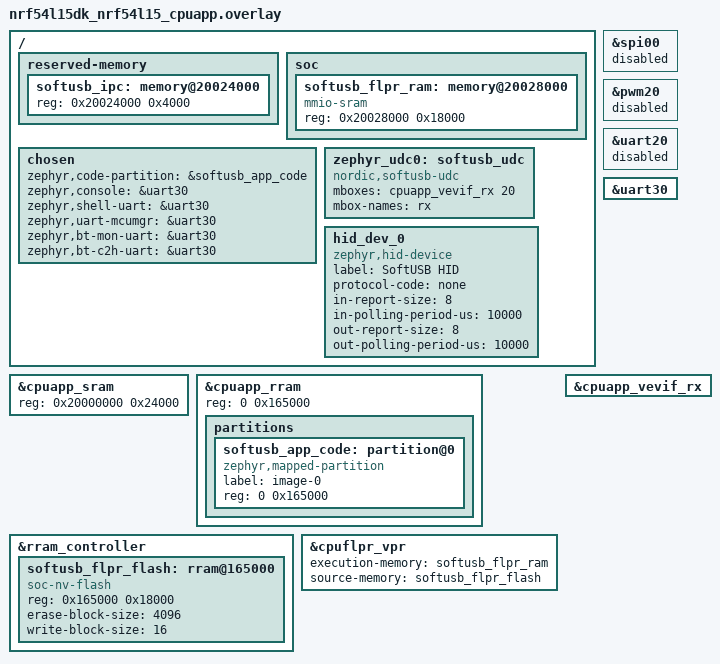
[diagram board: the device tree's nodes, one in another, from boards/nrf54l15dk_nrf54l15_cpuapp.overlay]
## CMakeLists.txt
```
cmake_minimum_required(VERSION 3.20.0)
list(APPEND DTS_ROOT ${CMAKE_CURRENT_SOURCE_DIR})
find_package(Zephyr REQUIRED HINTS $ENV{ZEPHYR_BASE})
project(softusb_device)
target_include_directories(app PRIVATE include ${ZEPHYR_BASE}/drivers/usb/udc)
target_sources(app PRIVATE src/main.c src/udc_softusb.c)
```

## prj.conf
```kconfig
CONFIG_MAIN_STACK_SIZE=4096
CONFIG_HEAP_MEM_POOL_SIZE=4096
CONFIG_GPIO=y
CONFIG_SPI=n
CONFIG_FLASH=n
CONFIG_PM=n
CONFIG_NORDIC_VPR_LAUNCHER=y
CONFIG_DCACHE=n
CONFIG_MBOX=y

CONFIG_USB_DEVICE_STACK_NEXT=y
CONFIG_USBD_HID_SUPPORT=y
CONFIG_UDC_BUF_COUNT=32

CONFIG_LOG=y
CONFIG_LOG_MODE_DEFERRED=y
CONFIG_USBD_LOG_LEVEL_WRN=y
CONFIG_USBD_HID_LOG_LEVEL_WRN=y
CONFIG_UDC_DRIVER_LOG_LEVEL_INF=y
```

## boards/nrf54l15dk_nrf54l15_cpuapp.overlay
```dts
/* App 144 KiB, IPC 16 KiB, FLPR 96 KiB. No overlap. */
/ {
    reserved-memory {
        #address-cells = <1>;
        #size-cells = <1>;
        ranges;
        softusb_ipc: memory@20024000 { reg = <0x20024000 0x4000>; };
    };
    soc {
        softusb_flpr_ram: memory@20028000 {
            compatible = "mmio-sram";
            reg = <0x20028000 0x18000>;
        };
    };
};
&cpuapp_sram { reg = <0x20000000 0x24000>; ranges = <0 0x20000000 0x24000>; };
&cpuapp_rram {
    reg = <0 0x165000>;
    ranges = <0 0 0x165000>;
    /delete-node/ partitions;
    partitions {
        #address-cells = <1>;
        #size-cells = <1>;
        softusb_app_code: partition@0 {
            compatible = "zephyr,mapped-partition";
            label = "image-0";
            reg = <0 0x165000>;
        };
    };
};
/ { chosen { zephyr,code-partition = &softusb_app_code; }; };
&rram_controller {
    softusb_flpr_flash: rram@165000 {
        compatible = "soc-nv-flash";
        reg = <0x165000 0x18000>;
        erase-block-size = <4096>;
        write-block-size = <16>;
    };
};
&cpuflpr_vpr {
    status = "okay";
    execution-memory = <&softusb_flpr_ram>;
    source-memory = <&softusb_flpr_flash>;
};
/* Never let flash/pinctrl claim the provisional bench pins. */
&spi00 { status = "disabled"; };
&pwm20 { status = "disabled"; };
/* Reserve P1.04..07 + P1.11/12 for future app-core PD control. */
&uart20 { status = "disabled"; };
&uart30 { status = "okay"; };
/ {
    chosen {
        zephyr,console = &uart30;
        zephyr,shell-uart = &uart30;
        zephyr,uart-mcumgr = &uart30;
        zephyr,bt-mon-uart = &uart30;
        zephyr,bt-c2h-uart = &uart30;
    };
};

&cpuapp_vevif_rx { status = "okay"; };

/ {
    zephyr_udc0: softusb_udc {
        compatible = "nordic,softusb-udc";
        mboxes = <&cpuapp_vevif_rx 20>;
        mbox-names = "rx";
        status = "okay";
    };

    /* Vendor-defined HID: harmless to the host (no keys, no pointer). LS
     * limits: 8-byte reports, interrupt endpoints polled every 10 ms.
     */
    hid_dev_0: hid_dev_0 {
        compatible = "zephyr,hid-device";
        label = "SoftUSB HID";
        protocol-code = "none";
        in-report-size = <8>;
        in-polling-period-us = <10000>;
        out-report-size = <8>;
        out-polling-period-us = <10000>;
    };
};
```

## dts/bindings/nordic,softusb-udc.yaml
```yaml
description: |
  SoftUSB low-speed USB device controller. The bus is bit-banged on P2.00 (D+)
  and P2.01 (D-) by an HPF personality on the FLPR core; the app core runs the
  Zephyr UDC driver. mboxes must name the FLPR->app VEVIF event as "rx".

compatible: "nordic,softusb-udc"

include: base.yaml
```

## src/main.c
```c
/*
 * SoftUSB demo: a low-speed vendor-defined HID device on the stock Zephyr
 * USB device stack (device_next), running over the FLPR bit-banged PHY.
 *
 * The vendor usage page means the host binds hidraw only: no keystrokes or
 * pointer motion. Each 8-byte OUT report is echoed back as the next IN
 * report; otherwise an IN report with a counter is sent every 500 ms.
 */
#include <string.h>
#include <zephyr/kernel.h>
#include <zephyr/sys/byteorder.h>
#include <zephyr/device.h>
#include <zephyr/usb/usbd.h>
#include <zephyr/usb/class/usbd_hid.h>
#include <zephyr/logging/log.h>
#include <zephyr/drivers/clock_control/nrf_clock_control.h>
#include "softusb_ipc.h"

LOG_MODULE_REGISTER(main, LOG_LEVEL_INF);

USBD_DEVICE_DEFINE(su_usbd, DEVICE_DT_GET(DT_NODELABEL(zephyr_udc0)), 0x2fe3, 0x0100);
USBD_DESC_LANG_DEFINE(su_lang);
USBD_DESC_MANUFACTURER_DEFINE(su_mfr, "HPF SoftUSB");
USBD_DESC_PRODUCT_DEFINE(su_product, "nRF54L15 FLPR LS HID");
USBD_DESC_CONFIG_DEFINE(su_cfg_desc, "LS configuration");
USBD_CONFIGURATION_DEFINE(su_config, 0, 50, &su_cfg_desc);

static const uint8_t report_desc[] = {
	0x06, 0x00, 0xFF, /* Usage Page (Vendor 0xFF00) */
	0x09, 0x01,       /* Usage (1) */
	0xA1, 0x01,       /* Collection (Application) */
	0x15, 0x00,       /*   Logical Minimum (0) */
	0x26, 0xFF, 0x00, /*   Logical Maximum (255) */
	0x75, 0x08,       /*   Report Size (8) */
	0x95, 0x08,       /*   Report Count (8) */
	0x09, 0x01,       /*   Usage (1) */
	0x81, 0x02,       /*   Input (Data, Var, Abs) */
	0x09, 0x01,       /*   Usage (1) */
	0x91, 0x02,       /*   Output (Data, Var, Abs) */
	0xC0,             /* End Collection */
};

UDC_STATIC_BUF_DEFINE(in_report, 8);
static uint8_t echo[8];
static volatile bool echo_pending;
static volatile bool hid_ready;
static K_SEM_DEFINE(report_done, 1, 1);
static K_SEM_DEFINE(echo_sem, 0, 1);

static void iface_ready(const struct device *dev, const bool ready)
{
	LOG_INF("HID interface %s", ready ? "ready" : "not ready");
	hid_ready = ready;
}

static int get_report(const struct device *dev, const uint8_t type, const uint8_t id,
		      const uint16_t len, uint8_t *const buf)
{
	return 0;
}

static int set_report(const struct device *dev, const uint8_t type, const uint8_t id,
		      const uint16_t len, const uint8_t *const buf)
{
	return 0;
}

static void output_report(const struct device *dev, const uint16_t len,
			  const uint8_t *const buf)
{
	memcpy(echo, buf, MIN(len, sizeof(echo)));
	echo_pending = true;
	k_sem_give(&echo_sem);
	LOG_INF("OUT report %02x %02x %02x %02x %02x %02x %02x %02x", echo[0], echo[1],
		echo[2], echo[3], echo[4], echo[5], echo[6], echo[7]);
}

static void input_report_done(const struct device *dev, const uint8_t *const report)
{
	k_sem_give(&report_done);
}

static const struct hid_device_ops hid_ops = {
	.iface_ready = iface_ready,
	.get_report = get_report,
	.set_report = set_report,
	.output_report = output_report,
	.input_report_done = input_report_done,
};

static void msg_cb(struct usbd_context *const ctx, const struct usbd_msg *const msg)
{
	LOG_INF("USBD message: %s", usbd_msg_type_string(msg->type));
}

static int usb_setup(void)
{
	int err;

	err = usbd_add_descriptor(&su_usbd, &su_lang);
	err = err ?: usbd_add_descriptor(&su_usbd, &su_mfr);
	err = err ?: usbd_add_descriptor(&su_usbd, &su_product);
	err = err ?: usbd_add_configuration(&su_usbd, USBD_SPEED_FS, &su_config);
	err = err ?: usbd_register_all_classes(&su_usbd, USBD_SPEED_FS, 1, NULL);
	err = err ?: usbd_device_set_code_triple(&su_usbd, USBD_SPEED_FS, 0, 0, 0);
	err = err ?: usbd_device_set_bcd_usb(&su_usbd, USBD_SPEED_FS, 0x0110);
	err = err ?: usbd_msg_register_cb(&su_usbd, msg_cb);
	err = err ?: usbd_init(&su_usbd);
	err = err ?: usbd_enable(&su_usbd);
	return err;
}

int main(void)
{
	const struct device *hid_dev = DEVICE_DT_GET(DT_NODELABEL(hid_dev_0));
	volatile struct su_ipc *ipc = SU_IPC;
	uint32_t counter = 0;
	int err;

	/* The FLPR's 128 MHz must be crystal-accurate: the RC-based clock was
	 * measured ~0.8% fast, enough to break 96-bit LS data packets.
	 */
	static struct onoff_client hfxo_cli;
	int res;

	sys_notify_init_spinwait(&hfxo_cli.notify);
	err = onoff_request(z_nrf_clock_control_get_onoff(CLOCK_CONTROL_NRF_SUBSYS_HF), &hfxo_cli);
	while (err >= 0 && sys_notify_fetch_result(&hfxo_cli.notify, &res) == -EAGAIN) {
		k_msleep(1);
	}
	LOG_INF("HFXO request %d", err);

	LOG_INF("SoftUSB LS device, waiting for FLPR");
	while (su_load(&ipc->flpr_ready) != SU_MAGIC) {
		k_msleep(1);
	}
	LOG_INF("FLPR ready, core %u Hz", ipc->st_core_hz);

	err = hid_device_register(hid_dev, report_desc, sizeof(report_desc), &hid_ops);
	if (err) {
		LOG_ERR("HID register failed %d", err);
		return 0;
	}
	err = usb_setup();
	if (err) {
		LOG_ERR("USB setup failed %d", err);
		return 0;
	}

	uint32_t last_stats = k_uptime_get_32();

	while (true) {
		(void)k_sem_take(&echo_sem, K_MSEC(500));
		if (hid_ready && k_sem_take(&report_done, K_MSEC(100)) == 0) {
			if (echo_pending) {
				memcpy(in_report, echo, sizeof(echo));
				echo_pending = false;
			} else {
				sys_put_le32(counter++, in_report);
				memcpy(&in_report[4], "SUSB", 4);
			}
			err = hid_device_submit_report(hid_dev, sizeof(echo), in_report);
			if (err) {
				k_sem_give(&report_done);
			}
		}
		if (k_uptime_get_32() - last_stats > 5000) {
			last_stats = k_uptime_get_32();
			LOG_INF("addr %u rx %u tok %u setup %u tx %u ack %u noack %u nak %u "
				"crc %u stuff %u sync %u to %u rst %u",
				ipc->address, ipc->st_rx_pkts, ipc->st_tokens_mine,
				ipc->st_setups, ipc->st_tx_pkts, ipc->st_in_acked,
				ipc->st_in_noack, ipc->st_naks, ipc->st_rx_crc, ipc->st_rx_stuff,
				ipc->st_rx_bad_sync, ipc->st_data_timeout, ipc->st_resets);
			LOG_HEXDUMP_INF((const uint8_t *)ipc->dbg_raw, 16, "last bad data");
			uint32_t m0 = ipc->dbg_mcycle;
			uint32_t u0 = k_cycle_get_32();

			k_msleep(100);
			uint32_t m1 = ipc->dbg_mcycle;
			uint32_t u1 = k_cycle_get_32();

			LOG_INF("bad len %u core %u cal300 %u mcycle/100ms %u (app cyc %u @%u)",
				ipc->dbg_len, ipc->st_core_hz, ipc->cal_mcycle_per_300, m1 - m0,
				u1 - u0, sys_clock_hw_cycles_per_sec());
		}
	}
	return 0;
}
```

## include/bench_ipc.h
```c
#ifndef SOFTUSB_BENCH_IPC_H
#define SOFTUSB_BENCH_IPC_H

#include <stdint.h>
#include <stddef.h>
#include <zephyr/devicetree.h>

#define BENCH_MAGIC 0x53554231u
#define BENCH_ABI 1u
#define BENCH_CAPACITY 1024u
#define BENCH_ARM_KEY 0x42454e43u
#define BENCH_DP (1u << 4) /* P2.00 -> VIO4 */
#define BENCH_DM (1u << 0) /* P2.01 -> VIO0 */
#define BENCH_SYNC (1u << 1) /* P2.02 -> VIO1 */
#define BENCH_RX_DP (1u << 3) /* P2.03 -> VIO3 */
#define BENCH_RX_DM (1u << 2) /* P2.04 -> VIO2 */
#define BENCH_DRIVE (BENCH_DP | BENCH_DM | BENCH_SYNC)
#define BENCH_SAMPLE 1u
#define BENCH_FS_EXPERIMENTAL 2u

enum bench_command { BENCH_CMD_DISARM=1, BENCH_CMD_ARM, BENCH_CMD_TX };
enum bench_result { BENCH_OK, BENCH_BAD_ABI, BENCH_BAD_COMMAND,
    BENCH_NOT_ARMED, BENCH_BAD_LENGTH, BENCH_BAD_FLAGS, BENCH_BAD_CELL };

/* Both cores: 32-bit little endian, naturally aligned. No pointers/size_t in ABI.
 * CPUAPP is the only request producer; FLPR the only completion producer.
 * Producer fills request/cells then release-publishes request_seq.
 * Consumer acquire-loads request_seq, finishes all reads/writes then release-
 * publishes completed_seq. Request/cells must stay immutable until completion.
 * No data cache. Only one in-flight request. Polling, no mailbox ISR in HRT.
 */
struct bench_ipc {
    uint32_t magic, abi, ready, request_seq, completed_seq;
    uint32_t command, key, count, flags;
    uint32_t result, armed, tx_count, sample_count;
    uint32_t vio_in, vio_dir, core_hz;
    uint32_t reserved[16];
    /* Cell = (following cell duration minus 1) << 16 | complete VIO OUT.
     * Only DP/DM/SYNC may be set. SE1 is rejected. */
    uint32_t cells[BENCH_CAPACITY];
    uint16_t samples[BENCH_CAPACITY];
};
_Static_assert(offsetof(struct bench_ipc, cells) == 128, "IPC header ABI");
_Static_assert(sizeof(struct bench_ipc) <= DT_REG_SIZE(DT_NODELABEL(softusb_ipc)), "IPC size");
#define BENCH_IPC ((volatile struct bench_ipc *)DT_REG_ADDR(DT_NODELABEL(softusb_ipc)))
static inline uint32_t bench_acquire(volatile uint32_t *p)
{
    return __atomic_load_n(p, __ATOMIC_ACQUIRE);
}
static inline void bench_release(volatile uint32_t *p, uint32_t value)
{
    __atomic_store_n(p, value, __ATOMIC_RELEASE);
}
#endif
```

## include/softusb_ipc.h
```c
/*
 * Shared-memory ABI between the app-core UDC driver and the FLPR LS engine.
 *
 * The FLPR answers every USB transaction on its own (ACK/NAK/STALL, data
 * toggles, address filtering) from buffers staged here; the app core only
 * moves payloads between this block and Zephyr's UDC buffers.
 *
 * Ownership is expressed with sequence counters, never with flags that both
 * sides write:
 *   IN  ep: app writes len/data/gen then bumps in[ep].req; FLPR bumps
 *           in[ep].done once the host ACKed (or the packet was dropped as stale).
 *           Pending <=> req != done. The app stages only when req == done.
 *   OUT ep: FLPR writes len/data/gen then bumps out[ep].full; app copies and
 *           sets out[ep].ack = full. FLPR NAKs while full != ack.
 * Every field has exactly one writer. No data cache on either core.
 */
#ifndef SOFTUSB_IPC_H
#define SOFTUSB_IPC_H

#include <stdint.h>
#include <stddef.h>
#include <zephyr/devicetree.h>

#define SU_MAGIC 0x53555342u /* "SUSB" */
#define SU_ABI 2u
#define SU_NUM_EP 4u
#define SU_MPS 8u

/* VIO bit masks (nRF54L15 P2 -> VIO map from HPF MSPI). */
#define SU_VIO_DP (1u << 4) /* P2.00 */
#define SU_VIO_DM (1u << 0) /* P2.01 */
#define SU_PIN_DP 0u        /* P2 pin numbers */
#define SU_PIN_DM 1u

/* VEVIF event the FLPR raises towards the app core (cpuapp_vevif_rx 20). */
#define SU_VEVIF_EVENT 20u

struct su_in_ep {
	uint32_t req;      /* app */
	uint32_t done;     /* FLPR */
	uint32_t len;      /* app: payload bytes 0..8 */
	uint32_t gen;      /* app: setup_seq this packet belongs to (EP0 only) */
	uint8_t data[12];  /* app: payload followed by CRC16 (LE) */
};

struct su_out_ep {
	uint32_t full;     /* FLPR */
	uint32_t ack;      /* app */
	uint32_t len;      /* FLPR */
	uint32_t gen;      /* FLPR: setup_seq when received */
	uint8_t data[12];  /* FLPR */
};

struct su_ipc {
	/* FLPR-written status. */
	uint32_t magic, abi, flpr_ready;
	uint32_t reset_seq;     /* bus resets seen */
	uint32_t setup_seq;     /* SETUP packets accepted */
	uint8_t setup[8];       /* last SETUP payload, valid when setup_seq moved */
	uint32_t address;       /* address in use */
	uint32_t event_seq;     /* bumped with every app-visible change */

	/* App-written control. FLPR ignores it until app_magic == SU_MAGIC, and
	 * only re-reads it when ctrl_seq changes (keeps the idle loop short).
	 */
	uint32_t app_magic;
	uint32_t ctrl_seq;
	uint32_t connect;       /* 1: internal pull-up on D- (attach) */
	uint32_t addr_req_seq;  /* bump to apply addr_req */
	uint32_t addr_req;
	uint32_t ep_in_enabled, ep_out_enabled;   /* bitmasks, EP0 always on */
	uint32_t ep_in_halt, ep_out_halt;         /* bitmasks, EP1.. */
	uint32_t ep0_stall_gen;  /* EP0 protocol stall while == setup_seq + 1 */
	uint32_t in_toggle_reset[SU_NUM_EP];   /* bump -> next IN DATA0 */
	uint32_t out_toggle_reset[SU_NUM_EP];  /* bump -> expect DATA0 */

	struct su_in_ep in[SU_NUM_EP];
	struct su_out_ep out[SU_NUM_EP];

	/* FLPR-written statistics. */
	uint32_t st_rx_pkts, st_rx_bad_sync, st_rx_bad_pid, st_rx_crc, st_rx_stuff;
	uint32_t st_rx_overflow, st_tokens_mine, st_tx_pkts, st_naks, st_stalls;
	uint32_t st_in_acked, st_in_noack, st_data_timeout, st_resets, st_setups;
	uint32_t st_toggle_dup, st_stale_drop, st_core_hz;
	uint32_t last_tokens[8]; /* ring of (pid<<16 | addr<<8 | ep) for debugging */
	uint32_t last_token_idx;
	uint32_t dbg_len;
	uint32_t cal_mcycle_per_300; /* mcycle delta over 300 WAIT0 periods, TOP=84 */
	uint32_t dbg_mcycle;          /* live mcycle, updated in the idle loop */
	uint8_t dbg_raw[16];
};

#define SU_IPC ((volatile struct su_ipc *)DT_REG_ADDR(DT_NODELABEL(softusb_ipc)))

_Static_assert(sizeof(struct su_ipc) <= DT_REG_SIZE(DT_NODELABEL(softusb_ipc)), "IPC size");

static inline uint32_t su_load(const volatile uint32_t *p)
{
	return __atomic_load_n(p, __ATOMIC_ACQUIRE);
}

static inline void su_store(volatile uint32_t *p, uint32_t v)
{
	__atomic_store_n(p, v, __ATOMIC_RELEASE);
}

#endif
```

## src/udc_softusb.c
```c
/*
 * Zephyr UDC driver for the SoftUSB FLPR low-speed engine.
 *
 * The FLPR answers all bus transactions by itself; this driver only moves
 * payload between Zephyr's UDC request buffers and the shared su_ipc block:
 * it stages IN packets (8 bytes + CRC16) one at a time, drains received OUT
 * packets and forwards SETUP/reset events to the USB device stack. A single
 * driver thread does all of this, woken by the FLPR's VEVIF event or by a
 * stack call, with a 1 ms poll as a safety net.
 *
 * The UDC API has no low-speed enum, so the device reports full speed to the
 * stack; descriptors must respect LS limits (EP0 MPS 8, interrupt EPs with
 * MPS <= 8 and bInterval >= 10 ms).
 */
#include <string.h>
#include <zephyr/kernel.h>
#include <zephyr/device.h>
#include <zephyr/drivers/mbox.h>
#include <zephyr/drivers/usb/udc.h>
#include <zephyr/logging/log.h>
#include "udc_common.h"
#include "softusb_ipc.h"

LOG_MODULE_REGISTER(udc_softusb, CONFIG_UDC_DRIVER_LOG_LEVEL);

#define DT_DRV_COMPAT nordic_softusb_udc

struct su_in_state {
	uint32_t off;      /* bytes of the head buffer already sent */
	uint32_t chunk;    /* bytes in the staged packet */
	bool staged;       /* a packet of the head buffer is with the FLPR */
	bool zlp_sent;
};

struct udc_softusb_config {
	size_t num_of_eps;
	struct udc_ep_config *ep_cfg_in;
	struct udc_ep_config *ep_cfg_out;
	k_thread_stack_t *thread_stk;
	size_t thread_stk_sz;
	struct mbox_dt_spec mbox_rx;
};

struct udc_softusb_data {
	struct k_thread thread_data;
	struct k_sem sem;
	struct su_in_state in[SU_NUM_EP];
	uint32_t reset_seen;
	uint32_t setup_seen;
};

static volatile struct su_ipc *const ipc = SU_IPC;

static uint16_t crc16(const uint8_t *p, size_t n)
{
	uint32_t c = 0xFFFFu;

	while (n--) {
		c ^= *p++;
		for (int k = 0; k < 8; k++) {
			c = (c & 1u) ? ((c >> 1) ^ 0xA001u) : (c >> 1);
		}
	}
	return (uint16_t)~c;
}

static void ctrl_changed(void)
{
	su_store(&ipc->ctrl_seq, ipc->ctrl_seq + 1u);
}

static void wake(const struct device *dev)
{
	struct udc_softusb_data *priv = udc_get_private(dev);

	k_sem_give(&priv->sem);
}

static void stage_in(const struct device *dev, uint32_t ep_idx)
{
	struct udc_softusb_data *priv = udc_get_private(dev);
	struct su_in_state *st = &priv->in[ep_idx];
	volatile struct su_in_ep *e = &ipc->in[ep_idx];
	struct udc_ep_config *cfg = udc_get_ep_cfg(dev, USB_EP_DIR_IN | ep_idx);
	struct net_buf *buf;

	/* Completion of the packet that was staged. */
	if (st->staged && su_load(&e->done) == e->req) {
		st->staged = false;
		st->off += st->chunk;
		buf = udc_buf_peek(cfg);
		if (buf != NULL && st->off >= buf->len) {
			bool need_zlp = udc_ep_buf_has_zlp(buf) && st->chunk == SU_MPS &&
					!st->zlp_sent && buf->len != 0;

			if (!need_zlp) {
				buf = udc_buf_get(cfg);
				st->off = 0;
				st->zlp_sent = false;
				udc_submit_ep_event(dev, buf, 0);
			}
		}
	}

	if (st->staged || e->req != su_load(&e->done) || cfg->stat.halted) {
		return;
	}
	buf = udc_buf_peek(cfg);
	if (buf == NULL) {
		return;
	}

	uint32_t n = MIN(SU_MPS, buf->len - MIN(st->off, buf->len));
	uint8_t pkt[SU_MPS + 2];

	if (st->off >= buf->len && buf->len != 0) {
		st->zlp_sent = true; /* trailing ZLP */
		n = 0;
	}
	memcpy(pkt, buf->data + st->off, n);
	uint16_t crc = crc16(pkt, n);

	pkt[n] = crc & 0xFF;
	pkt[n + 1] = crc >> 8;
	for (uint32_t i = 0; i < n + 2; i++) {
		e->data[i] = pkt[i];
	}
	e->len = n;
	e->gen = priv->setup_seen;
	st->chunk = n;
	st->staged = true;
	su_store(&e->req, e->req + 1u);
}

static void drain_out(const struct device *dev, uint32_t ep_idx)
{
	struct udc_softusb_data *priv = udc_get_private(dev);
	volatile struct su_out_ep *o = &ipc->out[ep_idx];
	struct udc_ep_config *cfg = udc_get_ep_cfg(dev, USB_EP_DIR_OUT | ep_idx);
	uint32_t full = su_load(&o->full);

	if (full == o->ack) {
		return;
	}
	if (ep_idx == 0 && o->gen != priv->setup_seen) {
		su_store(&o->ack, full); /* belongs to an older control transfer */
		return;
	}
	struct net_buf *buf = udc_buf_peek(cfg);

	if (buf == NULL || udc_get_buf_info(buf)->setup) {
		return; /* stack has not queued the data/status buffer yet: FLPR NAKs */
	}
	uint32_t len = o->len;
	uint32_t room = net_buf_tailroom(buf);
	uint32_t n = MIN(len, room);

	for (uint32_t i = 0; i < n; i++) {
		net_buf_add_u8(buf, o->data[i]);
	}
	su_store(&o->ack, full);
	if (len < udc_mps_ep_size(cfg) || net_buf_tailroom(buf) == 0) {
		buf = udc_buf_get(cfg);
		udc_submit_ep_event(dev, buf, 0);
	}
}

static void handle_events(const struct device *dev)
{
	const struct udc_softusb_config *config = dev->config;
	struct udc_softusb_data *priv = udc_get_private(dev);

	uint32_t rs = su_load(&ipc->reset_seq);

	if (rs != priv->reset_seen) {
		priv->reset_seen = rs;
		for (size_t i = 0; i < config->num_of_eps; i++) {
			priv->in[i].staged = false;
			priv->in[i].off = 0;
			priv->in[i].zlp_sent = false;
		}
		LOG_INF("bus reset");
		udc_submit_event(dev, UDC_EVT_RESET, 0);
	}

	uint32_t ss = su_load(&ipc->setup_seq);

	if (ss != priv->setup_seen) {
		uint8_t setup[8];
		uint32_t again;

		do {
			ss = su_load(&ipc->setup_seq);
			for (int i = 0; i < 8; i++) {
				setup[i] = ipc->setup[i];
			}
			again = su_load(&ipc->setup_seq);
		} while (again != ss);

		priv->setup_seen = ss;
		priv->in[0].staged = false;
		priv->in[0].off = 0;
		priv->in[0].zlp_sent = false;
		LOG_DBG("setup %02x %02x %02x %02x %02x %02x %02x %02x", setup[0], setup[1],
			setup[2], setup[3], setup[4], setup[5], setup[6], setup[7]);
		udc_setup_received(dev, setup);
	}

	for (size_t i = 0; i < config->num_of_eps; i++) {
		drain_out(dev, i);
		stage_in(dev, i);
	}
}

static void softusb_thread(void *arg1, void *arg2, void *arg3)
{
	const struct device *dev = arg1;
	struct udc_softusb_data *priv = udc_get_private(dev);

	ARG_UNUSED(arg2);
	ARG_UNUSED(arg3);

	while (true) {
		(void)k_sem_take(&priv->sem, K_MSEC(1));
		if (!udc_is_enabled(dev)) {
			continue;
		}
		udc_lock_internal(dev, K_FOREVER);
		handle_events(dev);
		udc_unlock_internal(dev);
	}
}

static void mbox_cb(const struct device *mdev, mbox_channel_id_t ch, void *user_data,
		    struct mbox_msg *msg)
{
	ARG_UNUSED(mdev);
	ARG_UNUSED(ch);
	ARG_UNUSED(msg);
	wake(user_data);
}

static int udc_softusb_ep_enqueue(const struct device *dev, struct udc_ep_config *const cfg,
				  struct net_buf *buf)
{
	udc_buf_put(cfg, buf);
	wake(dev);
	return 0;
}

static int udc_softusb_ep_dequeue(const struct device *dev, struct udc_ep_config *const cfg)
{
	struct udc_softusb_data *priv = udc_get_private(dev);
	uint32_t idx = USB_EP_GET_IDX(cfg->addr);

	udc_ep_cancel_queued(dev, cfg);
	if (USB_EP_DIR_IS_IN(cfg->addr)) {
		/* A packet already staged may still go out; it is not tracked. */
		priv->in[idx].staged = false;
		priv->in[idx].off = 0;
		priv->in[idx].zlp_sent = false;
	}
	return 0;
}

static int udc_softusb_ep_enable(const struct device *dev, struct udc_ep_config *const cfg)
{
	uint32_t idx = USB_EP_GET_IDX(cfg->addr);

	if (idx == 0) {
		return 0;
	}
	if (USB_EP_DIR_IS_IN(cfg->addr)) {
		ipc->in_toggle_reset[idx]++;
		ipc->ep_in_enabled |= BIT(idx);
	} else {
		ipc->out_toggle_reset[idx]++;
		ipc->ep_out_enabled |= BIT(idx);
	}
	ctrl_changed();
	LOG_DBG("enable ep 0x%02x mps %u", cfg->addr, udc_mps_ep_size(cfg));
	return 0;
}

static int udc_softusb_ep_disable(const struct device *dev, struct udc_ep_config *const cfg)
{
	uint32_t idx = USB_EP_GET_IDX(cfg->addr);

	if (idx == 0) {
		return 0;
	}
	if (USB_EP_DIR_IS_IN(cfg->addr)) {
		ipc->ep_in_enabled &= ~BIT(idx);
	} else {
		ipc->ep_out_enabled &= ~BIT(idx);
	}
	ctrl_changed();
	return 0;
}

static int udc_softusb_ep_set_halt(const struct device *dev, struct udc_ep_config *const cfg)
{
	struct udc_softusb_data *priv = udc_get_private(dev);
	uint32_t idx = USB_EP_GET_IDX(cfg->addr);

	if (idx == 0) {
		/* Protocol stall: ends with the next SETUP (FLPR compares gens). */
		ipc->ep0_stall_gen = priv->setup_seen + 1u;
		return 0;
	}
	if (USB_EP_DIR_IS_IN(cfg->addr)) {
		ipc->ep_in_halt |= BIT(idx);
	} else {
		ipc->ep_out_halt |= BIT(idx);
	}
	cfg->stat.halted = true;
	return 0;
}

static int udc_softusb_ep_clear_halt(const struct device *dev, struct udc_ep_config *const cfg)
{
	uint32_t idx = USB_EP_GET_IDX(cfg->addr);

	if (idx == 0) {
		return 0;
	}
	if (USB_EP_DIR_IS_IN(cfg->addr)) {
		ipc->ep_in_halt &= ~BIT(idx);
		ipc->in_toggle_reset[idx]++;
	} else {
		ipc->ep_out_halt &= ~BIT(idx);
		ipc->out_toggle_reset[idx]++;
	}
	ctrl_changed();
	cfg->stat.halted = false;
	wake(dev);
	return 0;
}

static int udc_softusb_set_address(const struct device *dev, const uint8_t addr)
{
	/* The FLPR already switched after the SET_ADDRESS status stage; this
	 * keeps both sides consistent (and handles address 0 on reset).
	 */
	ipc->addr_req = addr;
	ipc->addr_req_seq++;
	ctrl_changed();
	LOG_INF("address %u", addr);
	return 0;
}

static int udc_softusb_host_wakeup(const struct device *dev)
{
	return -ENOTSUP;
}

static enum udc_bus_speed udc_softusb_device_speed(const struct device *dev)
{
	return UDC_BUS_SPEED_FS; /* the UDC API has no low-speed value */
}

static int udc_softusb_enable(const struct device *dev)
{
	ipc->connect = 1u;
	ctrl_changed();
	LOG_INF("connect (D- pull-up on)");
	return 0;
}

static int udc_softusb_disable(const struct device *dev)
{
	ipc->connect = 0u;
	ctrl_changed();
	return 0;
}

static int udc_softusb_init(const struct device *dev)
{
	if (udc_ep_enable_internal(dev, USB_CONTROL_EP_OUT, USB_EP_TYPE_CONTROL, SU_MPS, 0) ||
	    udc_ep_enable_internal(dev, USB_CONTROL_EP_IN, USB_EP_TYPE_CONTROL, SU_MPS, 0)) {
		LOG_ERR("Failed to enable control endpoint");
		return -EIO;
	}
	return 0;
}

static int udc_softusb_shutdown(const struct device *dev)
{
	if (udc_ep_disable_internal(dev, USB_CONTROL_EP_OUT) ||
	    udc_ep_disable_internal(dev, USB_CONTROL_EP_IN)) {
		return -EIO;
	}
	return 0;
}

static int udc_softusb_preinit(const struct device *dev)
{
	const struct udc_softusb_config *config = dev->config;
	struct udc_softusb_data *priv = udc_get_private(dev);
	struct udc_data *data = dev->data;
	int err;

	k_mutex_init(&data->mutex);
	k_sem_init(&priv->sem, 0, 1);
	data->caps.rwup = false;
	data->caps.mps0 = UDC_MPS0_8;
	data->caps.addr_before_status = false;

	for (size_t i = 0; i < config->num_of_eps; i++) {
		struct udc_ep_config *o = &config->ep_cfg_out[i];
		struct udc_ep_config *in = &config->ep_cfg_in[i];

		o->caps.out = 1;
		in->caps.in = 1;
		if (i == 0) {
			o->caps.control = 1;
			in->caps.control = 1;
		} else {
			/* Low speed: interrupt endpoints only. */
			o->caps.interrupt = 1;
			in->caps.interrupt = 1;
		}
		o->caps.mps = SU_MPS;
		in->caps.mps = SU_MPS;
		o->addr = USB_EP_DIR_OUT | i;
		in->addr = USB_EP_DIR_IN | i;
		err = udc_register_ep(dev, o);
		if (!err) {
			err = udc_register_ep(dev, in);
		}
		if (err) {
			LOG_ERR("Failed to register endpoint");
			return err;
		}
	}

	/* Take ownership of the app-written half of the IPC block. */
	ipc->connect = 0;
	ipc->ep_in_enabled = 0;
	ipc->ep_out_enabled = 0;
	ipc->ep_in_halt = 0;
	ipc->ep_out_halt = 0;
	ipc->ep0_stall_gen = 0;
	for (size_t i = 0; i < SU_NUM_EP; i++) {
		ipc->in[i].req = ipc->in[i].done;
		ipc->out[i].ack = ipc->out[i].full;
	}
	priv->reset_seen = ipc->reset_seq;
	priv->setup_seen = ipc->setup_seq;
	su_store(&ipc->app_magic, SU_MAGIC);
	ctrl_changed();

	if (config->mbox_rx.dev != NULL && device_is_ready(config->mbox_rx.dev)) {
		err = mbox_register_callback_dt(&config->mbox_rx, mbox_cb, (void *)dev);
		if (!err) {
			err = mbox_set_enabled_dt(&config->mbox_rx, true);
		}
		if (err) {
			LOG_WRN("VEVIF event unavailable (%d), polling only", err);
		}
	}

	k_thread_create(&priv->thread_data, config->thread_stk, config->thread_stk_sz,
			softusb_thread, (void *)dev, NULL, NULL, K_PRIO_COOP(8), K_ESSENTIAL,
			K_NO_WAIT);
	k_thread_name_set(&priv->thread_data, "udc_softusb");
	return 0;
}

static void udc_softusb_lock(const struct device *dev)
{
	udc_lock_internal(dev, K_FOREVER);
}

static void udc_softusb_unlock(const struct device *dev)
{
	udc_unlock_internal(dev);
}

static const struct udc_api udc_softusb_api = {
	.lock = udc_softusb_lock,
	.unlock = udc_softusb_unlock,
	.device_speed = udc_softusb_device_speed,
	.init = udc_softusb_init,
	.enable = udc_softusb_enable,
	.disable = udc_softusb_disable,
	.shutdown = udc_softusb_shutdown,
	.set_address = udc_softusb_set_address,
	.host_wakeup = udc_softusb_host_wakeup,
	.ep_enable = udc_softusb_ep_enable,
	.ep_disable = udc_softusb_ep_disable,
	.ep_set_halt = udc_softusb_ep_set_halt,
	.ep_clear_halt = udc_softusb_ep_clear_halt,
	.ep_enqueue = udc_softusb_ep_enqueue,
	.ep_dequeue = udc_softusb_ep_dequeue,
};

#define UDC_SOFTUSB_DEVICE_DEFINE(n)                                                       \
	K_THREAD_STACK_DEFINE(udc_softusb_stack_##n, 2048);                                \
	static struct udc_ep_config ep_cfg_out_##n[SU_NUM_EP];                             \
	static struct udc_ep_config ep_cfg_in_##n[SU_NUM_EP];                              \
	static const struct udc_softusb_config udc_softusb_config_##n = {                  \
		.num_of_eps = SU_NUM_EP,                                                   \
		.ep_cfg_in = ep_cfg_in_##n,                                                \
		.ep_cfg_out = ep_cfg_out_##n,                                              \
		.thread_stk = udc_softusb_stack_##n,                                       \
		.thread_stk_sz = K_THREAD_STACK_SIZEOF(udc_softusb_stack_##n),             \
		.mbox_rx = MBOX_DT_SPEC_INST_GET(n, rx),                                   \
	};                                                                                 \
	static struct udc_softusb_data udc_priv_##n;                                       \
	static struct udc_data udc_data_##n = {                                            \
		.mutex = Z_MUTEX_INITIALIZER(udc_data_##n.mutex),                          \
		.priv = &udc_priv_##n,                                                     \
	};                                                                                 \
	DEVICE_DT_INST_DEFINE(n, udc_softusb_preinit, NULL, &udc_data_##n,                 \
			      &udc_softusb_config_##n, POST_KERNEL,                        \
			      CONFIG_KERNEL_INIT_PRIORITY_DEVICE, &udc_softusb_api);

DT_INST_FOREACH_STATUS_OKAY(UDC_SOFTUSB_DEVICE_DEFINE)
```
